VERSION ""

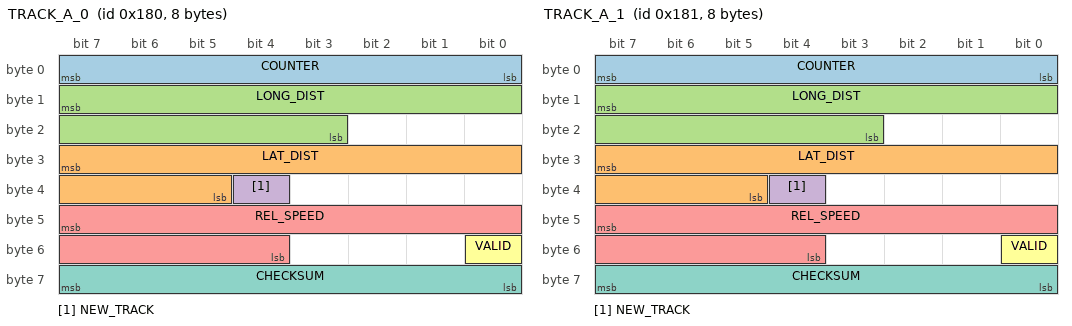
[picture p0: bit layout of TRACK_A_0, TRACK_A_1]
BO_ 384 TRACK_A_0: 8 XXX
 SG_ COUNTER : 7|8@0+ (1,0) [0|255] "" XXX
 SG_ LAT_DIST : 31|11@0- (0.04,0) [-50|50] "m" XXX
 SG_ LONG_DIST : 15|13@0+ (0.04,0) [0|300] "m" XXX
 SG_ NEW_TRACK : 36|1@0+ (1,0) [0|1] "" XXX
 SG_ REL_SPEED : 47|12@0- (0.025,0) [-100|100] "m/s" XXX
 SG_ VALID : 48|1@0+ (1,0) [0|1] "" XXX
 SG_ CHECKSUM : 63|8@0+ (1,0) [0|255] "" XXX

BO_ 385 TRACK_A_1: 8 XXX
 SG_ COUNTER : 7|8@0+ (1,0) [0|255] "" XXX
 SG_ LAT_DIST : 31|11@0- (0.04,0) [-50|50] "m" XXX
 SG_ LONG_DIST : 15|13@0+ (0.04,0) [0|300] "m" XXX
 SG_ NEW_TRACK : 36|1@0+ (1,0) [0|1] "" XXX
 SG_ REL_SPEED : 47|12@0- (0.025,0) [-100|100] "m/s" XXX
 SG_ VALID : 48|1@0+ (1,0) [0|1] "" XXX
 SG_ CHECKSUM : 63|8@0+ (1,0) [0|255] "" XXX

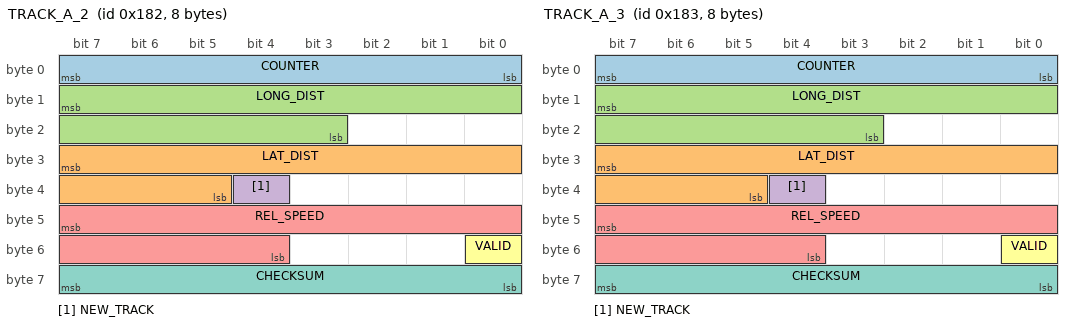
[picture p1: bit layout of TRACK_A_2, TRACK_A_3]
BO_ 386 TRACK_A_2: 8 XXX
 SG_ COUNTER : 7|8@0+ (1,0) [0|255] "" XXX
 SG_ LAT_DIST : 31|11@0- (0.04,0) [-50|50] "m" XXX
 SG_ LONG_DIST : 15|13@0+ (0.04,0) [0|300] "m" XXX
 SG_ NEW_TRACK : 36|1@0+ (1,0) [0|1] "" XXX
 SG_ REL_SPEED : 47|12@0- (0.025,0) [-100|100] "m/s" XXX
 SG_ VALID : 48|1@0+ (1,0) [0|1] "" XXX
 SG_ CHECKSUM : 63|8@0+ (1,0) [0|255] "" XXX

BO_ 387 TRACK_A_3: 8 XXX
 SG_ COUNTER : 7|8@0+ (1,0) [0|255] "" XXX
 SG_ LAT_DIST : 31|11@0- (0.04,0) [-50|50] "m" XXX
 SG_ LONG_DIST : 15|13@0+ (0.04,0) [0|300] "m" XXX
 SG_ NEW_TRACK : 36|1@0+ (1,0) [0|1] "" XXX
 SG_ REL_SPEED : 47|12@0- (0.025,0) [-100|100] "m/s" XXX
 SG_ VALID : 48|1@0+ (1,0) [0|1] "" XXX
 SG_ CHECKSUM : 63|8@0+ (1,0) [0|255] "" XXX

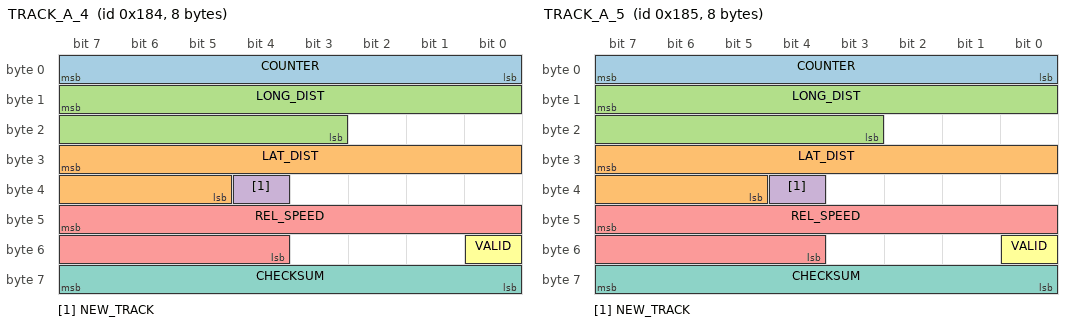
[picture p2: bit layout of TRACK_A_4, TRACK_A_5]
BO_ 388 TRACK_A_4: 8 XXX
 SG_ COUNTER : 7|8@0+ (1,0) [0|255] "" XXX
 SG_ LAT_DIST : 31|11@0- (0.04,0) [-50|50] "m" XXX
 SG_ LONG_DIST : 15|13@0+ (0.04,0) [0|300] "m" XXX
 SG_ NEW_TRACK : 36|1@0+ (1,0) [0|1] "" XXX
 SG_ REL_SPEED : 47|12@0- (0.025,0) [-100|100] "m/s" XXX
 SG_ VALID : 48|1@0+ (1,0) [0|1] "" XXX
 SG_ CHECKSUM : 63|8@0+ (1,0) [0|255] "" XXX

BO_ 389 TRACK_A_5: 8 XXX
 SG_ COUNTER : 7|8@0+ (1,0) [0|255] "" XXX
 SG_ LAT_DIST : 31|11@0- (0.04,0) [-50|50] "m" XXX
 SG_ LONG_DIST : 15|13@0+ (0.04,0) [0|300] "m" XXX
 SG_ NEW_TRACK : 36|1@0+ (1,0) [0|1] "" XXX
 SG_ REL_SPEED : 47|12@0- (0.025,0) [-100|100] "m/s" XXX
 SG_ VALID : 48|1@0+ (1,0) [0|1] "" XXX
 SG_ CHECKSUM : 63|8@0+ (1,0) [0|255] "" XXX

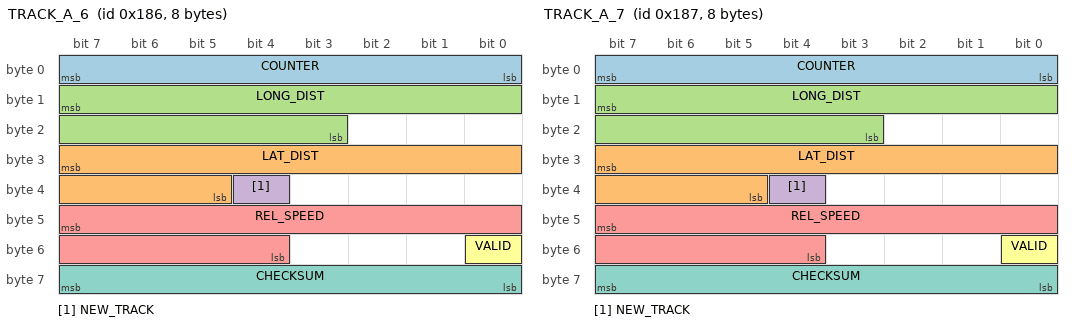
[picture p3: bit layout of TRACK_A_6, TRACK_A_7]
BO_ 390 TRACK_A_6: 8 XXX
 SG_ COUNTER : 7|8@0+ (1,0) [0|255] "" XXX
 SG_ LAT_DIST : 31|11@0- (0.04,0) [-50|50] "m" XXX
 SG_ LONG_DIST : 15|13@0+ (0.04,0) [0|300] "m" XXX
 SG_ NEW_TRACK : 36|1@0+ (1,0) [0|1] "" XXX
 SG_ REL_SPEED : 47|12@0- (0.025,0) [-100|100] "m/s" XXX
 SG_ VALID : 48|1@0+ (1,0) [0|1] "" XXX
 SG_ CHECKSUM : 63|8@0+ (1,0) [0|255] "" XXX

BO_ 391 TRACK_A_7: 8 XXX
 SG_ COUNTER : 7|8@0+ (1,0) [0|255] "" XXX
 SG_ LAT_DIST : 31|11@0- (0.04,0) [-50|50] "m" XXX
 SG_ LONG_DIST : 15|13@0+ (0.04,0) [0|300] "m" XXX
 SG_ NEW_TRACK : 36|1@0+ (1,0) [0|1] "" XXX
 SG_ REL_SPEED : 47|12@0- (0.025,0) [-100|100] "m/s" XXX
 SG_ VALID : 48|1@0+ (1,0) [0|1] "" XXX
 SG_ CHECKSUM : 63|8@0+ (1,0) [0|255] "" XXX

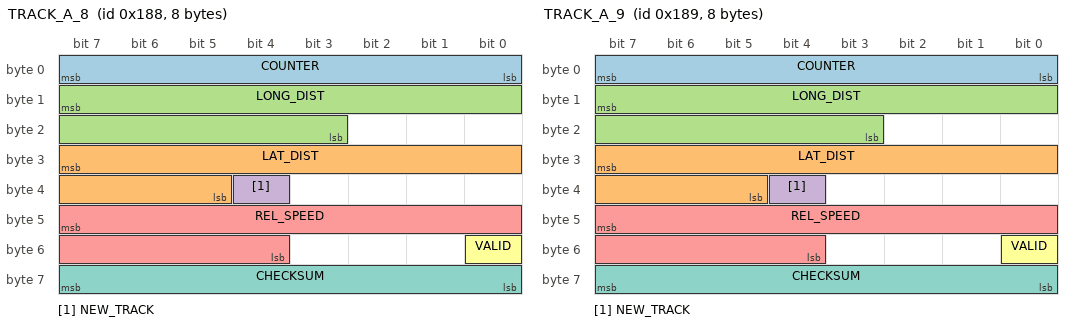
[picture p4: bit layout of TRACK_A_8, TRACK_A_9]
BO_ 392 TRACK_A_8: 8 XXX
 SG_ COUNTER : 7|8@0+ (1,0) [0|255] "" XXX
 SG_ LAT_DIST : 31|11@0- (0.04,0) [-50|50] "m" XXX
 SG_ LONG_DIST : 15|13@0+ (0.04,0) [0|300] "m" XXX
 SG_ NEW_TRACK : 36|1@0+ (1,0) [0|1] "" XXX
 SG_ REL_SPEED : 47|12@0- (0.025,0) [-100|100] "m/s" XXX
 SG_ VALID : 48|1@0+ (1,0) [0|1] "" XXX
 SG_ CHECKSUM : 63|8@0+ (1,0) [0|255] "" XXX

BO_ 393 TRACK_A_9: 8 XXX
 SG_ COUNTER : 7|8@0+ (1,0) [0|255] "" XXX
 SG_ LAT_DIST : 31|11@0- (0.04,0) [-50|50] "m" XXX
 SG_ LONG_DIST : 15|13@0+ (0.04,0) [0|300] "m" XXX
 SG_ NEW_TRACK : 36|1@0+ (1,0) [0|1] "" XXX
 SG_ REL_SPEED : 47|12@0- (0.025,0) [-100|100] "m/s" XXX
 SG_ VALID : 48|1@0+ (1,0) [0|1] "" XXX
 SG_ CHECKSUM : 63|8@0+ (1,0) [0|255] "" XXX

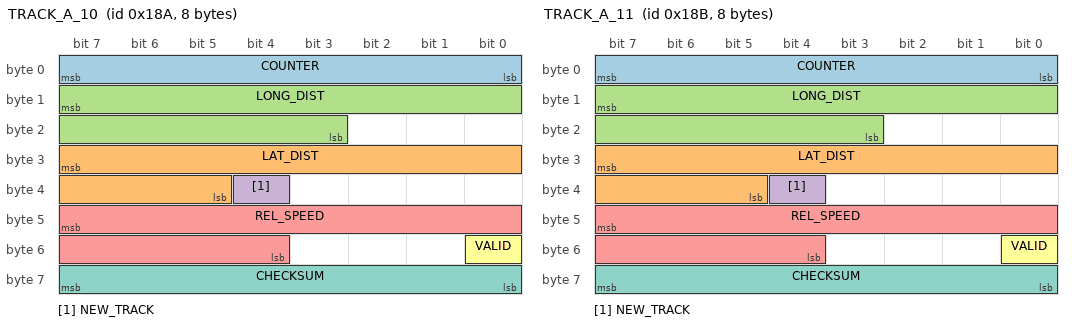
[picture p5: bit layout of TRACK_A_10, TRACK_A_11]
BO_ 394 TRACK_A_10: 8 XXX
 SG_ COUNTER : 7|8@0+ (1,0) [0|255] "" XXX
 SG_ LAT_DIST : 31|11@0- (0.04,0) [-50|50] "m" XXX
 SG_ LONG_DIST : 15|13@0+ (0.04,0) [0|300] "m" XXX
 SG_ NEW_TRACK : 36|1@0+ (1,0) [0|1] "" XXX
 SG_ REL_SPEED : 47|12@0- (0.025,0) [-100|100] "m/s" XXX
 SG_ VALID : 48|1@0+ (1,0) [0|1] "" XXX
 SG_ CHECKSUM : 63|8@0+ (1,0) [0|255] "" XXX

BO_ 395 TRACK_A_11: 8 XXX
 SG_ COUNTER : 7|8@0+ (1,0) [0|255] "" XXX
 SG_ LAT_DIST : 31|11@0- (0.04,0) [-50|50] "m" XXX
 SG_ LONG_DIST : 15|13@0+ (0.04,0) [0|300] "m" XXX
 SG_ NEW_TRACK : 36|1@0+ (1,0) [0|1] "" XXX
 SG_ REL_SPEED : 47|12@0- (0.025,0) [-100|100] "m/s" XXX
 SG_ VALID : 48|1@0+ (1,0) [0|1] "" XXX
 SG_ CHECKSUM : 63|8@0+ (1,0) [0|255] "" XXX

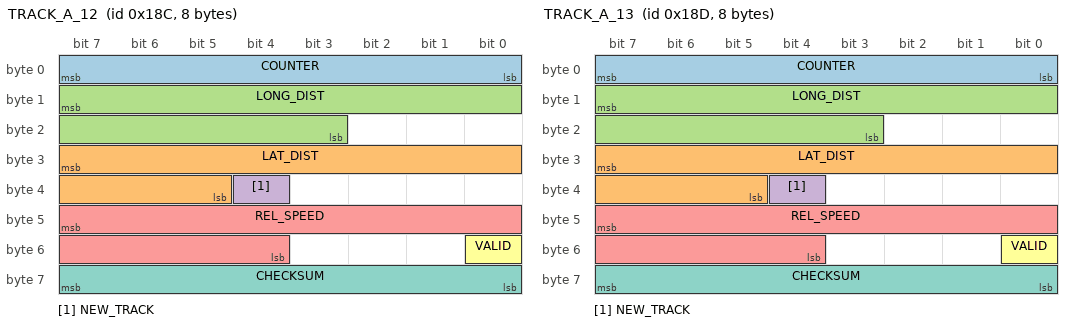
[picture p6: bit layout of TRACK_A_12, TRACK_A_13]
BO_ 396 TRACK_A_12: 8 XXX
 SG_ COUNTER : 7|8@0+ (1,0) [0|255] "" XXX
 SG_ LAT_DIST : 31|11@0- (0.04,0) [-50|50] "m" XXX
 SG_ LONG_DIST : 15|13@0+ (0.04,0) [0|300] "m" XXX
 SG_ NEW_TRACK : 36|1@0+ (1,0) [0|1] "" XXX
 SG_ REL_SPEED : 47|12@0- (0.025,0) [-100|100] "m/s" XXX
 SG_ VALID : 48|1@0+ (1,0) [0|1] "" XXX
 SG_ CHECKSUM : 63|8@0+ (1,0) [0|255] "" XXX

BO_ 397 TRACK_A_13: 8 XXX
 SG_ COUNTER : 7|8@0+ (1,0) [0|255] "" XXX
 SG_ LAT_DIST : 31|11@0- (0.04,0) [-50|50] "m" XXX
 SG_ LONG_DIST : 15|13@0+ (0.04,0) [0|300] "m" XXX
 SG_ NEW_TRACK : 36|1@0+ (1,0) [0|1] "" XXX
 SG_ REL_SPEED : 47|12@0- (0.025,0) [-100|100] "m/s" XXX
 SG_ VALID : 48|1@0+ (1,0) [0|1] "" XXX
 SG_ CHECKSUM : 63|8@0+ (1,0) [0|255] "" XXX

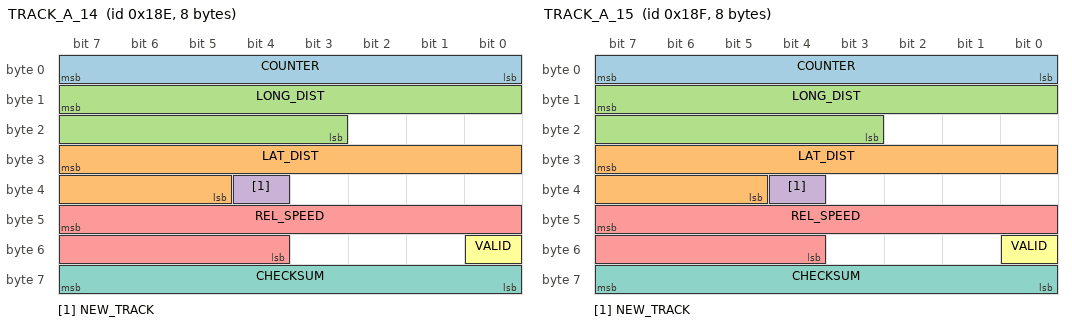
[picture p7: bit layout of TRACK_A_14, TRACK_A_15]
BO_ 398 TRACK_A_14: 8 XXX
 SG_ COUNTER : 7|8@0+ (1,0) [0|255] "" XXX
 SG_ LAT_DIST : 31|11@0- (0.04,0) [-50|50] "m" XXX
 SG_ LONG_DIST : 15|13@0+ (0.04,0) [0|300] "m" XXX
 SG_ NEW_TRACK : 36|1@0+ (1,0) [0|1] "" XXX
 SG_ REL_SPEED : 47|12@0- (0.025,0) [-100|100] "m/s" XXX
 SG_ VALID : 48|1@0+ (1,0) [0|1] "" XXX
 SG_ CHECKSUM : 63|8@0+ (1,0) [0|255] "" XXX

BO_ 399 TRACK_A_15: 8 XXX
 SG_ COUNTER : 7|8@0+ (1,0) [0|255] "" XXX
 SG_ LAT_DIST : 31|11@0- (0.04,0) [-50|50] "m" XXX
 SG_ LONG_DIST : 15|13@0+ (0.04,0) [0|300] "m" XXX
 SG_ NEW_TRACK : 36|1@0+ (1,0) [0|1] "" XXX
 SG_ REL_SPEED : 47|12@0- (0.025,0) [-100|100] "m/s" XXX
 SG_ VALID : 48|1@0+ (1,0) [0|1] "" XXX
 SG_ CHECKSUM : 63|8@0+ (1,0) [0|255] "" XXX

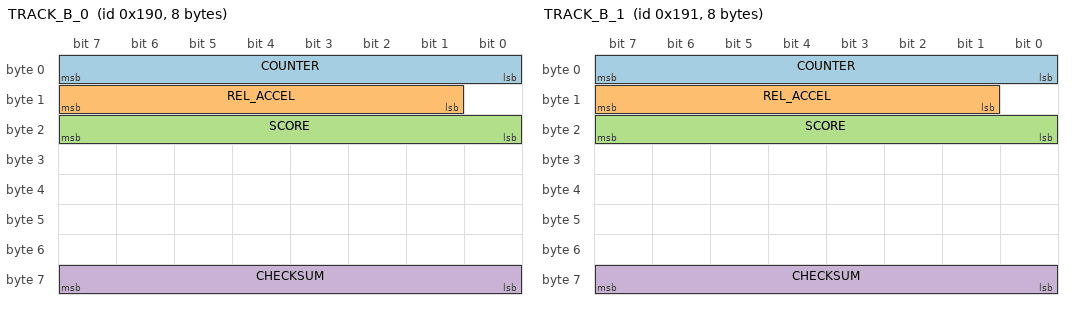
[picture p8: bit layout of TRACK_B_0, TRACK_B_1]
BO_ 400 TRACK_B_0: 8 XXX
 SG_ COUNTER : 7|8@0+ (1,0) [0|255] "" XXX
 SG_ REL_ACCEL : 15|7@0- (1,0) [-64|63] "" XXX
 SG_ SCORE : 23|8@0+ (1,0) [0|100] "" XXX
 SG_ CHECKSUM : 63|8@0+ (1,0) [0|255] "" XXX

BO_ 401 TRACK_B_1: 8 XXX
 SG_ COUNTER : 7|8@0+ (1,0) [0|255] "" XXX
 SG_ REL_ACCEL : 15|7@0- (1,0) [-64|63] "" XXX
 SG_ SCORE : 23|8@0+ (1,0) [0|100] "" XXX
 SG_ CHECKSUM : 63|8@0+ (1,0) [0|255] "" XXX

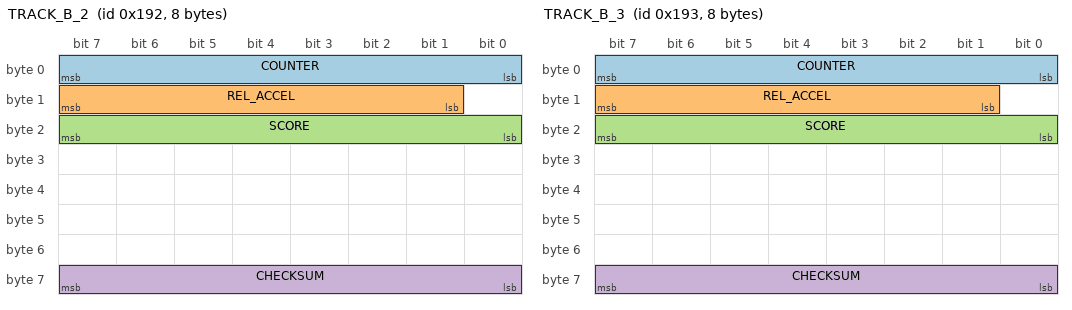
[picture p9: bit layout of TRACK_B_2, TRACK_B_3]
BO_ 402 TRACK_B_2: 8 XXX
 SG_ COUNTER : 7|8@0+ (1,0) [0|255] "" XXX
 SG_ REL_ACCEL : 15|7@0- (1,0) [-64|63] "" XXX
 SG_ SCORE : 23|8@0+ (1,0) [0|100] "" XXX
 SG_ CHECKSUM : 63|8@0+ (1,0) [0|255] "" XXX

BO_ 403 TRACK_B_3: 8 XXX
 SG_ COUNTER : 7|8@0+ (1,0) [0|255] "" XXX
 SG_ REL_ACCEL : 15|7@0- (1,0) [-64|63] "" XXX
 SG_ SCORE : 23|8@0+ (1,0) [0|100] "" XXX
 SG_ CHECKSUM : 63|8@0+ (1,0) [0|255] "" XXX

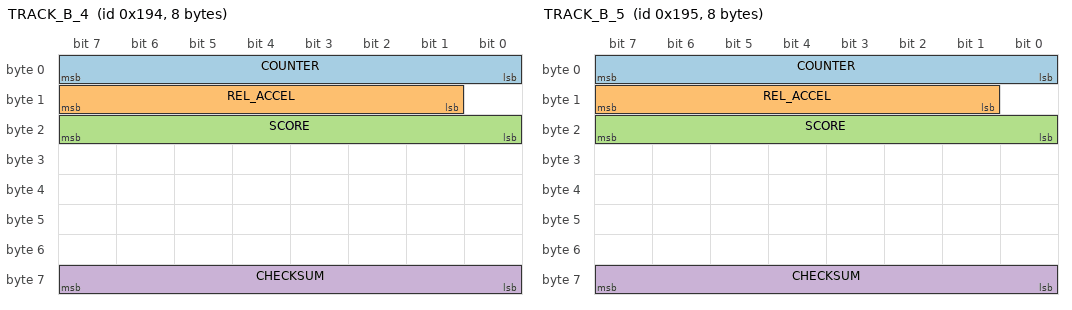
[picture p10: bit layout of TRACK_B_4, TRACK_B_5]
BO_ 404 TRACK_B_4: 8 XXX
 SG_ COUNTER : 7|8@0+ (1,0) [0|255] "" XXX
 SG_ REL_ACCEL : 15|7@0- (1,0) [-64|63] "" XXX
 SG_ SCORE : 23|8@0+ (1,0) [0|100] "" XXX
 SG_ CHECKSUM : 63|8@0+ (1,0) [0|255] "" XXX

BO_ 405 TRACK_B_5: 8 XXX
 SG_ COUNTER : 7|8@0+ (1,0) [0|255] "" XXX
 SG_ REL_ACCEL : 15|7@0- (1,0) [-64|63] "" XXX
 SG_ SCORE : 23|8@0+ (1,0) [0|100] "" XXX
 SG_ CHECKSUM : 63|8@0+ (1,0) [0|255] "" XXX

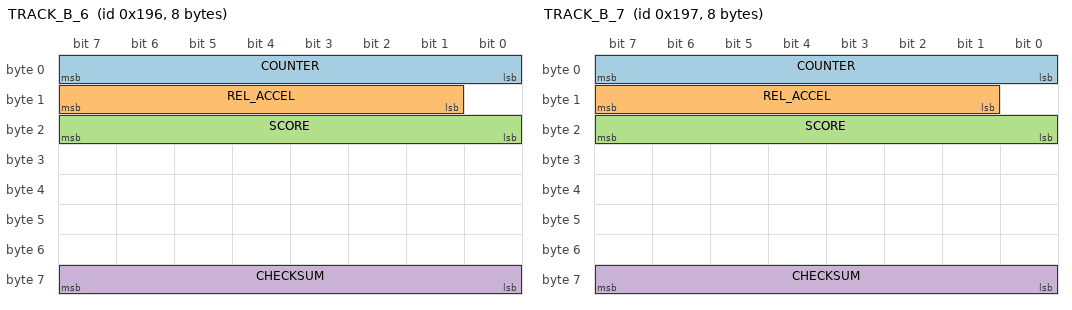
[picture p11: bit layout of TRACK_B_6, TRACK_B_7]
BO_ 406 TRACK_B_6: 8 XXX
 SG_ COUNTER : 7|8@0+ (1,0) [0|255] "" XXX
 SG_ REL_ACCEL : 15|7@0- (1,0) [-64|63] "" XXX
 SG_ SCORE : 23|8@0+ (1,0) [0|100] "" XXX
 SG_ CHECKSUM : 63|8@0+ (1,0) [0|255] "" XXX

BO_ 407 TRACK_B_7: 8 XXX
 SG_ COUNTER : 7|8@0+ (1,0) [0|255] "" XXX
 SG_ REL_ACCEL : 15|7@0- (1,0) [-64|63] "" XXX
 SG_ SCORE : 23|8@0+ (1,0) [0|100] "" XXX
 SG_ CHECKSUM : 63|8@0+ (1,0) [0|255] "" XXX

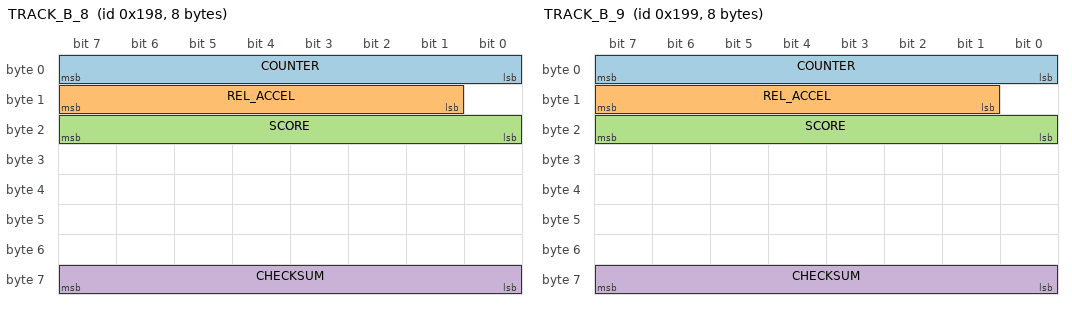
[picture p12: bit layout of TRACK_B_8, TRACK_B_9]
BO_ 408 TRACK_B_8: 8 XXX
 SG_ COUNTER : 7|8@0+ (1,0) [0|255] "" XXX
 SG_ REL_ACCEL : 15|7@0- (1,0) [-64|63] "" XXX
 SG_ SCORE : 23|8@0+ (1,0) [0|100] "" XXX
 SG_ CHECKSUM : 63|8@0+ (1,0) [0|255] "" XXX

BO_ 409 TRACK_B_9: 8 XXX
 SG_ COUNTER : 7|8@0+ (1,0) [0|255] "" XXX
 SG_ REL_ACCEL : 15|7@0- (1,0) [-64|63] "" XXX
 SG_ SCORE : 23|8@0+ (1,0) [0|100] "" XXX
 SG_ CHECKSUM : 63|8@0+ (1,0) [0|255] "" XXX

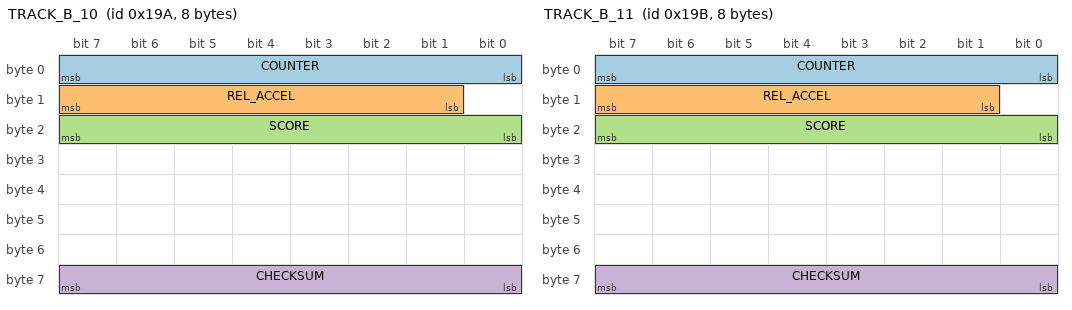
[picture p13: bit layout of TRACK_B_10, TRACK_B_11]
BO_ 410 TRACK_B_10: 8 XXX
 SG_ COUNTER : 7|8@0+ (1,0) [0|255] "" XXX
 SG_ REL_ACCEL : 15|7@0- (1,0) [-64|63] "" XXX
 SG_ SCORE : 23|8@0+ (1,0) [0|100] "" XXX
 SG_ CHECKSUM : 63|8@0+ (1,0) [0|255] "" XXX

BO_ 411 TRACK_B_11: 8 XXX
 SG_ COUNTER : 7|8@0+ (1,0) [0|255] "" XXX
 SG_ REL_ACCEL : 15|7@0- (1,0) [-64|63] "" XXX
 SG_ SCORE : 23|8@0+ (1,0) [0|100] "" XXX
 SG_ CHECKSUM : 63|8@0+ (1,0) [0|255] "" XXX

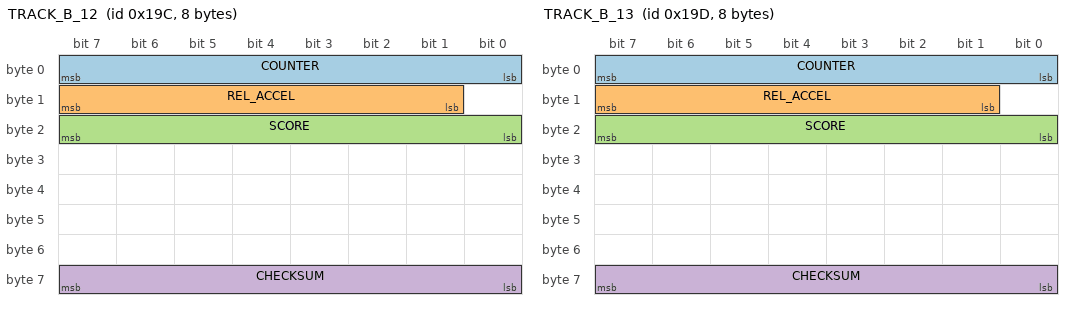
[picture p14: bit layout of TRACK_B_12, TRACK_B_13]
BO_ 412 TRACK_B_12: 8 XXX
 SG_ COUNTER : 7|8@0+ (1,0) [0|255] "" XXX
 SG_ REL_ACCEL : 15|7@0- (1,0) [-64|63] "" XXX
 SG_ SCORE : 23|8@0+ (1,0) [0|100] "" XXX
 SG_ CHECKSUM : 63|8@0+ (1,0) [0|255] "" XXX

BO_ 413 TRACK_B_13: 8 XXX
 SG_ COUNTER : 7|8@0+ (1,0) [0|255] "" XXX
 SG_ REL_ACCEL : 15|7@0- (1,0) [-64|63] "" XXX
 SG_ SCORE : 23|8@0+ (1,0) [0|100] "" XXX
 SG_ CHECKSUM : 63|8@0+ (1,0) [0|255] "" XXX

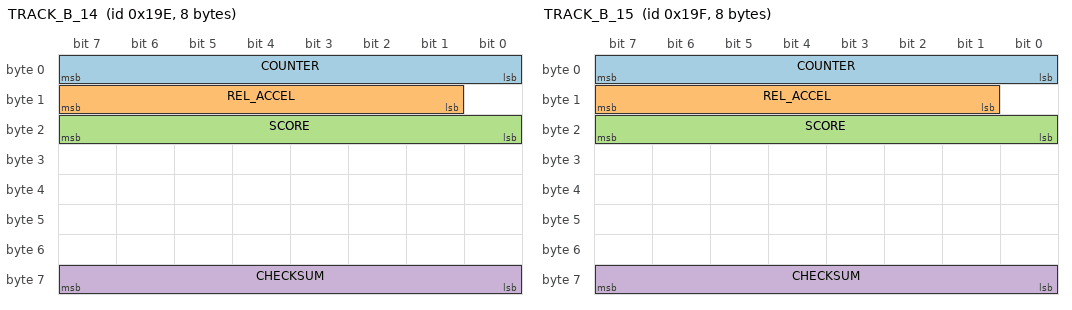
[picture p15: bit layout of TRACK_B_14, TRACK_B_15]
BO_ 414 TRACK_B_14: 8 XXX
 SG_ COUNTER : 7|8@0+ (1,0) [0|255] "" XXX
 SG_ REL_ACCEL : 15|7@0- (1,0) [-64|63] "" XXX
 SG_ SCORE : 23|8@0+ (1,0) [0|100] "" XXX
 SG_ CHECKSUM : 63|8@0+ (1,0) [0|255] "" XXX

BO_ 415 TRACK_B_15: 8 XXX
 SG_ COUNTER : 7|8@0+ (1,0) [0|255] "" XXX
 SG_ REL_ACCEL : 15|7@0- (1,0) [-64|63] "" XXX
 SG_ SCORE : 23|8@0+ (1,0) [0|100] "" XXX
 SG_ CHECKSUM : 63|8@0+ (1,0) [0|255] "" XXX

BO_ 576 NEW_MSG_1: 8 XXX
 SG_ NEW_SIGNAL_1 : 15|7@0+ (1,0) [0|127] "" XXX
 SG_ NEW_SIGNAL_2 : 23|8@0+ (1,0) [0|255] "" XXX

CM_ SG_ 85 BrakePedalActive2 "Active during braking";
CM_ SG_ 85 NEW_SIGNAL_1 "Not yet figured out.";
CM_ SG_ 85 BrakePedalActive "Brake pedal pushed";
CM_ SG_ 8 SteeringDirection "1=Right turn, 0=Left turn. Steering wheel pointing left or right from center (0 deg).";
CM_ SG_ 8 RelativeTurnDirection "1=Right turn, 0=Left turn. Steering wheel currently turning the way.";
CM_ SG_ 101 NEW_SIGNAL_1 "Rate of something?";
CM_ SG_ 192 TransmissionGear "0 = 1st gear, 1= 2nd gear...";
CM_ SG_ 681 TurnSignal "0 = Nothing, 1= Left, 3=Right";
CM_ SG_ 681 HighBeamOn "1=HighBeam On, 0=HighBeam Off";
CM_ SG_ 48 ACCStatusTracking "ACC Tracking vehicle, distance control.";
CM_ SG_ 48 ACCStatusOnOff "Turns one after pressing on/off button on steering wheeel";
CM_ SG_ 48 ACCStatusActive "ACC Active";
CM_ SG_ 48 FCWSomething "All bit set during fcw";
CM_ SG_ 48 StatusSomething "Some status changes when zeroing DTCs";
CM_ SG_ 208 TrqLim "Used in checksum calculation, Limit directional torque based on the number.";
CM_ SG_ 208 Checksum "Checksum calculated as a one-complement addition of LKAAngleRequest+LKADirection+Unkown, Zeros used to pad missing bits.";
CM_ SG_ 208 SET_X_02 "Bit 0 = Vibrate steering wheel., Bit 1 = Heartbeat";
CM_ SG_ 352 LkaDimLine "Not true, but follows lka steer direction.";
CM_ SG_ 352 NEW_SIGNAL_1 "Turned one. Got LKA service needed can this be the one?";
CM_ SG_ 640 SpeedTarget "SpeedTarget ACC (noisy bf starting acc Jumps from 0->252->0)";
CM_ SG_ 853 TargetSpeedOdo "Probably target speed odo";
CM_ SG_ 853 LaneMarkingsOdo "Bit 3=Left lane, Bit 2=Right lane, Bit 1=LKA on?, Bit 0=?";
CM_ SG_ 709 SpeedTargetACC "SpeedTargetACC";
CM_ SG_ 224 rate_of_something "Seems to be some kind of torque rather than rate.";
CM_ SG_ 224 OneDuringDriving "Set to 1 when vehicle is rolling.";
CM_ SG_ 293 byte7 "Bit0=0 when gearshift in park, else 1";
CM_ SG_ 293 LKAActive "Bit0=0 when gear in park otherwise =1, Bit1=1 when LKA Active, 0 when not active. Bit2=? Bit3=?";
CM_ SG_ 16 ACCOnOffBtn "Cruise control on/off button pressed";
CM_ SG_ 16 ACCSetBtn "Acc Set button (+) pressed";
CM_ SG_ 16 ACCStopBtn "ACC Stop button pressed";
CM_ SG_ 16 ACCResumeBtn "ACC Resume button pressed";
CM_ SG_ 16 ACCMinusBtn "ACC Minus (-) button pressed";
CM_ SG_ 16 TimeGapIncreaseBtn "Increase the time gap on ACC";
CM_ SG_ 16 TimeGapDecreaseBtn "Decrease the time gap on ACC";
CM_ SG_ 245 counter0 "Speed based counter";
CM_ SG_ 245 WhlSpdLF "Wheel speed left front";
CM_ SG_ 245 WhlSpdRF "Wheel speed right front";
CM_ SG_ 288 WhlSpdLR "Wheel speed left rear";
CM_ SG_ 288 WhlSpdRR "Wheel speed right rear";
CM_ SG_ 64 RPMSomething "TransmissionOutput?";
CM_ SG_ 64 GearShifter "P=0, R=1, N=2, D=3";
CM_ SG_ 272 VehicleSpeedSignal "km/h";
CM_ SG_ 432 BrakePress0 "Brake being pressed";
CM_ SG_ 432 BrakePress1 "Brake being pressed";
CM_ SG_ 432 BrakeStatus "ACC brake?";
CM_ SG_ 437 Counter0 "Related to braking? Maybe one per wheel?";
CM_ SG_ 437 Counter1 "Related to braking? Maybe one per wheel?";
CM_ SG_ 437 Counter2 "Related to braking? Maybe one per wheel?";
CM_ SG_ 437 Counter3 "Related to braking? Maybe one per wheel?";
CM_ SG_ 114 NEW_SIGNAL_1 "Jumped from 0 -> 120 during start. Makes triangle from time to time";
CM_ SG_ 608 NEW_SIGNAL_1 "Status?";
CM_ SG_ 608 NEW_SIGNAL_2 "Classification of object?";
CM_ SG_ 608 Distance "Distance to object in front.";
CM_ SG_ 968 PassengerSeatBelt "1 = Seatbalt latched";
CM_ SG_ 968 DriverSeatBelt "1=Seatbelt latched";
